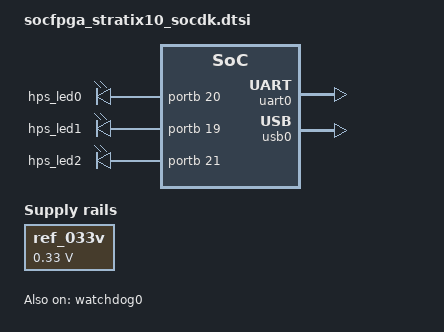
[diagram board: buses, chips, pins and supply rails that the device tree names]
// SPDX-License-Identifier: GPL-2.0-only
/*
 * Copyright Altera Corporation (C) 2026. All rights reserved.
 */

#include "socfpga_stratix10.dtsi"

/ {
	aliases {
		serial0 = &uart0;
		ethernet0 = &gmac0;
		ethernet1 = &gmac1;
		ethernet2 = &gmac2;
	};

	chosen {
		stdout-path = "serial0:115200n8";
	};

	leds {
		compatible = "gpio-leds";
		led-hps0 {
			label = "hps_led0";
			gpios = <&portb 20 GPIO_ACTIVE_HIGH>;
		};

		led-hps1 {
			label = "hps_led1";
			gpios = <&portb 19 GPIO_ACTIVE_HIGH>;
		};

		led-hps2 {
			label = "hps_led2";
			gpios = <&portb 21 GPIO_ACTIVE_HIGH>;
		};
	};

	memory@80000000 {
		device_type = "memory";
		/* We expect the bootloader to fill in the reg */
		reg = <0 0x80000000 0 0>;
	};

	ref_033v: regulator-0v33-ref {
		compatible = "regulator-fixed";
		regulator-name = "0.33V";
		regulator-min-microvolt = <330000>;
		regulator-max-microvolt = <330000>;
	};
};

&gpio1 {
	status = "okay";
};

&osc1 {
	clock-frequency = <25000000>;
};

&uart0 {
	status = "okay";
};

&usb0 {
	status = "okay";
	disable-over-current;
};

&watchdog0 {
	status = "okay";
};
